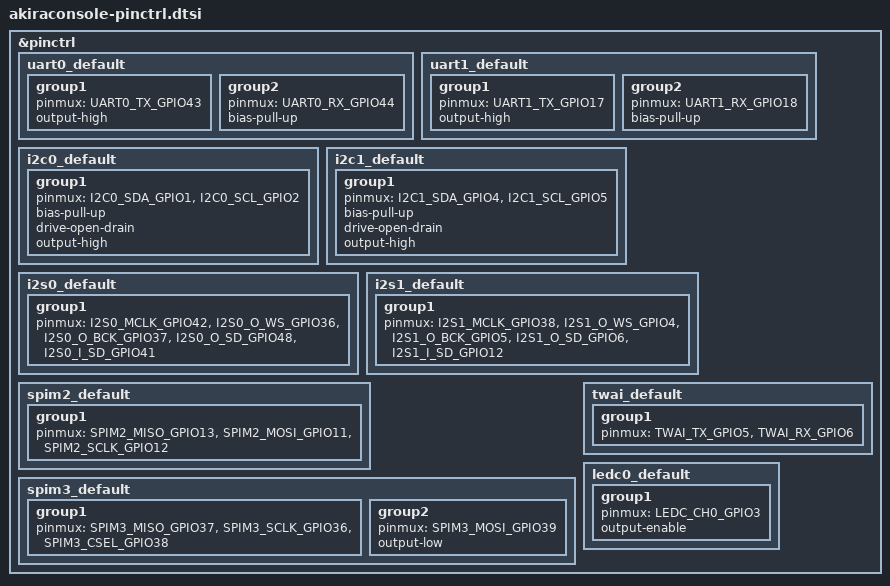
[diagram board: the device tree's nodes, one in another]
/*TODO: add all peripherals and stuff*/

#include <zephyr/dt-bindings/pinctrl/esp-pinctrl-common.h>
#include <dt-bindings/pinctrl/esp32s3-pinctrl.h>
#include <zephyr/dt-bindings/pinctrl/esp32s3-gpio-sigmap.h>

&pinctrl {
	uart0_default: uart0_default {
		group1 {
			pinmux = <UART0_TX_GPIO43>;
			output-high;
		};

		group2 {
			pinmux = <UART0_RX_GPIO44>;
			bias-pull-up;
		};
	};

	uart1_default: uart1_default {
		group1 {
			pinmux = <UART1_TX_GPIO17>;
			output-high;
		};

		group2 {
			pinmux = <UART1_RX_GPIO18>;
			bias-pull-up;
		};
	};

	i2c0_default: i2c0_default {
		group1 {
			pinmux = <I2C0_SDA_GPIO1>,
				 <I2C0_SCL_GPIO2>;
			bias-pull-up;
			drive-open-drain;
			output-high;
		};
	};

	i2c1_default: i2c1_default {
		group1 {
			pinmux = <I2C1_SDA_GPIO4>,
				 <I2C1_SCL_GPIO5>;
			bias-pull-up;
			drive-open-drain;
			output-high;
		};
	};

	i2s0_default: i2s0_default {
		group1 {
			pinmux = <I2S0_MCLK_GPIO42>,
				 <I2S0_O_WS_GPIO36>,
				 <I2S0_O_BCK_GPIO37>,
				 <I2S0_O_SD_GPIO48>,
				 <I2S0_I_SD_GPIO41>;
		};
	};

	i2s1_default: i2s1_default {
		group1 {
			pinmux = <I2S1_MCLK_GPIO38>,
				 <I2S1_O_WS_GPIO4>,
				 <I2S1_O_BCK_GPIO5>,
				 <I2S1_O_SD_GPIO6>,
				 <I2S1_I_SD_GPIO12>;
		};
	};

	spim2_default: spim2_default {
		group1 {
			/* MOSI перенесён сюда — output-low убран                  */
			/* SPIM2_CSEL_GPIO10 убран — CS управляется через cs-gpios */
			pinmux = <SPIM2_MISO_GPIO13>,
				 <SPIM2_MOSI_GPIO11>,
				 <SPIM2_SCLK_GPIO12>;
		};
		/* group2 с output-low на MOSI удалена полностью */
	};

	spim3_default: spim3_default {
		group1 {
			pinmux = <SPIM3_MISO_GPIO37>,
				 <SPIM3_SCLK_GPIO36>,
				 <SPIM3_CSEL_GPIO38>;
		};

		group2 {
			pinmux = <SPIM3_MOSI_GPIO39>;
			output-low;
		};
	};

	twai_default: twai_default {
		group1 {
			pinmux = <TWAI_TX_GPIO5>,
				 <TWAI_RX_GPIO6>;
		};
	};

	/* Backlight PWM — LEDC channel 0 on GPIO3 */
	ledc0_default: ledc0_default {
		group1 {
			pinmux = <LEDC_CH0_GPIO3>;
			output-enable;
		};
	};
};
